# GD32L23x register map
File version: 1.0
CPU: CM23 r0p0, little endian, MPU, FPU, 4 interrupt priority bits
Registers are 32-bit, read-write, reset 0x0 unless marked. A register's access mark holds for its fields unless they carry their own. Offsets are from the block's base; [hi:lo] are bit positions; {n}, {i} and the like mark numbered series.

## FWDGT — free watchdog timer
Base 0x40003000
0x00 CTL wo — Control register
  [15:0] CMD — Key value
0x04 PSC — Prescaler register
  [2:0] PSC — Prescaler divider
0x08 RLD reset 0xFFF — Reload register
  [11:0] RLD — Watchdog counter reload value
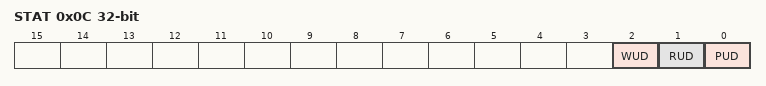
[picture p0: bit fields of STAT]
0x0C STAT ro — Status register
  [2] WUD — Watchdog counter window value update
  [1] RUD — Watchdog counter reload value update
  [0] PUD — Watchdog prescaler value update
0x10 WND reset 0xFFF — Window register
  [11:0] WND — Watchdog counter window value

## GPIOA — General-purpose I/Os
Base 0x48000000
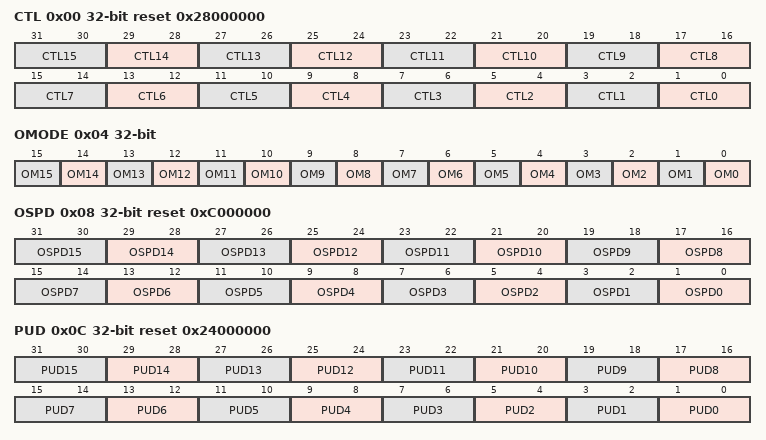
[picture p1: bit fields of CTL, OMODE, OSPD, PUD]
0x00 CTL reset 0x28000000 — GPIO port control register
  [2n+1:2n] CTL{n} (n=0..15) — Port x configuration bits (y = 0..15)
0x04 OMODE — GPIO port output type register
  [n] OM{n} (n=0..15) — Port x configuration bit {n}
0x08 OSPD reset 0xC000000 — GPIO port output speed register
  [2n+1:2n] OSPD{n} (n=0..15) — Port x configuration bits (y = 0..15)
0x0C PUD reset 0x24000000 — GPIO port pull-up/pull-down register
  [2n+1:2n] PUD{n} (n=0..15) — Port x configuration bits (y = 0..15)
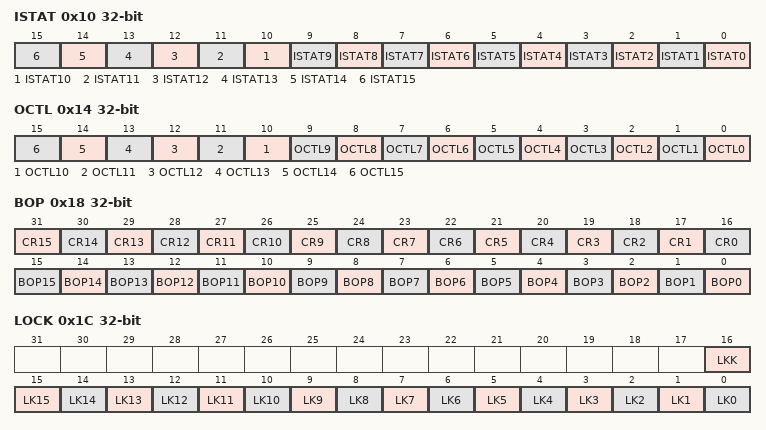
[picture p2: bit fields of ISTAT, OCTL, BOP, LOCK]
0x10 ISTAT ro — GPIO port input data register
  [n] ISTAT{n} (n=0..15) — Port input data (y = 0..15)
0x14 OCTL — GPIO port output data register
  [n] OCTL{n} (n=0..15) — Port output data (y = 0..15)
0x18 BOP wo — GPIO port bit set/reset register
  [n+16] CR{n} (n=1..15) — Port x reset bit y (y = 0..15)
  [16] CR0 — Port x reset bit y (y= 0..15)
  [n] BOP{n} (n=0..15) — Port x set bit y (y= 0..15)
0x1C LOCK — GPIO port configuration lock register
  [16] LKK — Port x lock bit y
  [n] LK{n} (n=0..15) — Port x lock bit y (y= 0..15)
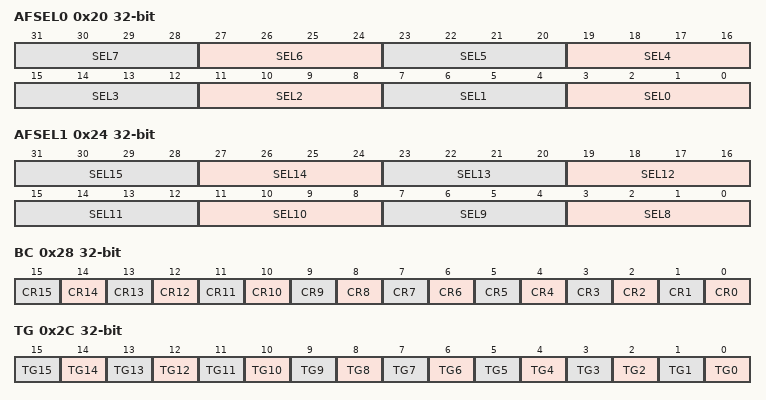
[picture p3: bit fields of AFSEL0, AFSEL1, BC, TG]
0x20 AFSEL0 — GPIO alternate function low register
  [4n+3:4n] SEL{n} (n=0..7) — Alternate function selection for port x bit y (y = 0..7)
0x24 AFSEL1 — GPIO alternate function register 1
  [4n-29:4n-32] SEL{n} (n=8..15) — Alternate function selection for port x bit y (y = 8..15)
0x28 BC wo — Port bit reset register
  [n] CR{n} (n=0..15) — Port cleat bit
0x2C TG wo — Port bit toggle register
  [n] TG{n} (n=0..15) — Port toggle bit

## GPIOB — General-purpose I/Os
Base 0x48000400
Registers as GPIOA; these are added or differ:
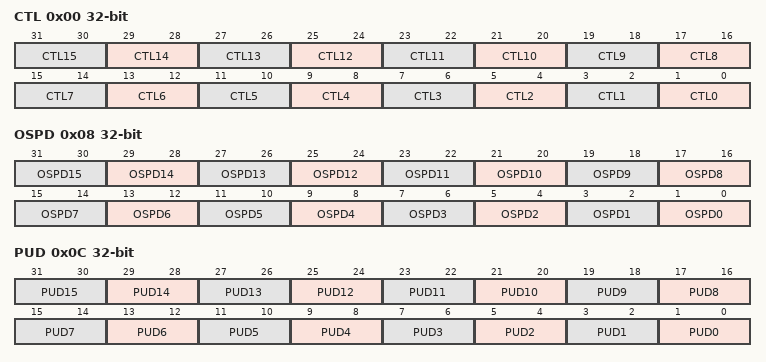
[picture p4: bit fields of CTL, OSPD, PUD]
0x00 CTL — GPIO port control register
  [2n+1:2n] CTL{n} (n=0..15) — Port x configuration bits (y = 0..15)
0x08 OSPD — GPIO port output speed register
  [2n+1:2n] OSPD{n} (n=0..15) — Port x configuration bits (y = 0..15)
0x0C PUD — GPIO port pull-up/pull-down register
  [2n+1:2n] PUD{n} (n=0..15) — Port x configuration bits (y = 0..15)

## GPIOC — General-purpose I/Os
Base 0x48000800
Registers as GPIOB, without LOCK.

## GPIOD — General-purpose I/Os
Base 0x48000C00
Registers as GPIOB, without LOCK.

## GPIOF — General-purpose I/Os
Base 0x48001400
Registers as GPIOB, without LOCK, AFSEL0, AFSEL1; these are added or differ:
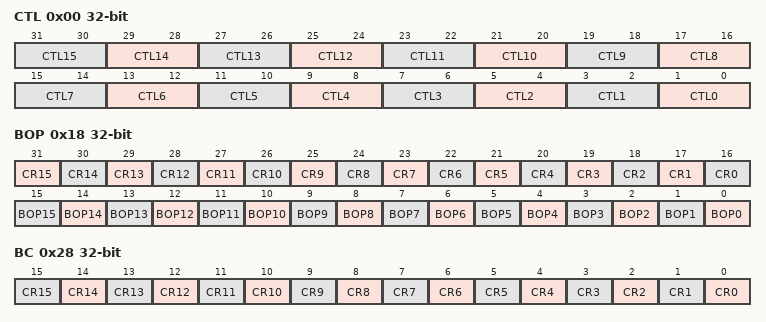
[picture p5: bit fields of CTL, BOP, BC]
0x00 CTL — GPIOF port control register
  [2n+1:2n] CTL{n} (n=0..15) — Port x configuration bits (y = 0..15)
0x18 BOP wo — GPIO port bit set/reset register
  [n+16] CR{n} (n=1..15) — Port x reset bit y (y = 0..15)
  [16] CR0 — Port x set bit y (y= 0..15)
  [n] BOP{n} (n=0..15) — Port x set bit y (y= 0..15)
0x28 BC wo — Port bit reset register
  [n] CR{n} (n=0..15) — Port x Reset bit y

## NVIC — Nested Vectored Interrupt Controller
Base 0xE000E100
{0x0+4i} ISER{i} (i=0..15) — Interrupt Set Enable Register
  [31:0] SETENA
0x80 ICER0 — Interrupt Clear Enable Register
  [31:0] CLRENA
0x84 ICER1 — Interrupt Clear Enable Register
  [31:0] CLRENA
{0x84+4i} ICER{i} (i=2..15) — Interrupt Clear Enable Register
  [31:0] CLRENA
{0x100+4i} ISPR{i} (i=0..15) — Interrupt Set-Pending Register
  [31:0] SETPEND
{0x180+4i} ICPR{i} (i=0..15) — Interrupt Clear-Pending Register
  [31:0] CLRPEND
{0x200+4i} IABR{i} (i=0..15) — Interrupt Active bit Register
  [31:0] IABR
{0x280+4i} ITNS{i} (i=0..15) — Interrupt Active bit Register
  [31:0] ITNS
{0x300+i} IPR{i} 8-bit (i=0..31) — Interrupt Priority Register {i}
  [7:0] PRI_{i:02}
